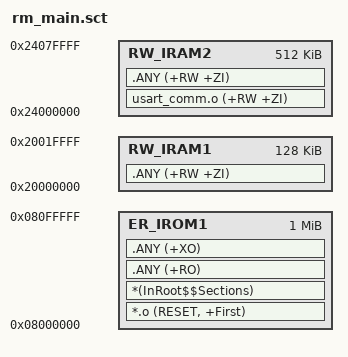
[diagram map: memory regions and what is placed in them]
; *************************************************************
; STM32H723 Scatter Loading - DMA 优化版
; *************************************************************

LR_IROM1 0x08000000 0x00100000  {    ; 1MB Flash (根据你的原配置)
  ER_IROM1 0x08000000 0x00100000  {
   *.o (RESET, +First)
   *(InRoot$$Sections)
   .ANY (+RO)
   .ANY (+XO)
  }
  
  ; DTCM (128K): 只放普通全局变量，不放 DMA 缓冲区
  RW_IRAM1 0x20000000 0x00020000  {
   .ANY (+RW +ZI)
  }
  
  ; AXI SRAM (512K): 强制 DMA 缓冲区在前
  RW_IRAM2 0x24000000 0x00080000  {   ; ← 改为 0x80000 (512KB)
   ; 关键：usart_comm.o 的变量先放（包含 dma_*_buf）
   usart_comm.o (+RW +ZI)
   
   ; 最后放其他所有文件（包括 Protocol 的结构体）
   .ANY (+RW +ZI)
  }
}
